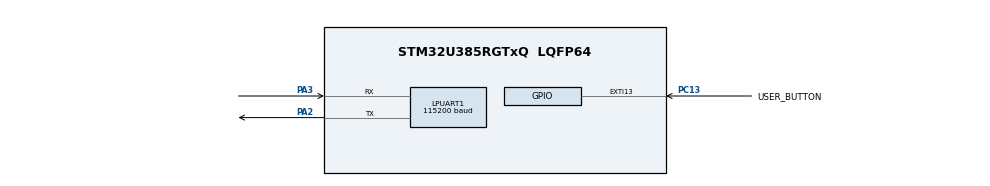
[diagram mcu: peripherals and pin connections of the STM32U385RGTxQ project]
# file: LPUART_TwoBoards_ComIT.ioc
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CORTEX_M33_NS.userName=CORTEX_M33
LPUART1.BaudRate=115200
LPUART1.ClockPrescaler=UART_PRESCALER_DIV1
LPUART1.DMADisableonRxErrorParam=UART_ADVFEATURE_DMA_ENABLEONRXERROR
LPUART1.DataInvertParam=UART_ADVFEATURE_DATAINV_DISABLE
LPUART1.FIFOMode=UART_FIFOMODE_DISABLE
LPUART1.MSBFirstParam=UART_ADVFEATURE_MSBFIRST_DISABLE
LPUART1.Mode=UART_MODE_TX_RX
LPUART1.OneBitSampling=UART_ONE_BIT_SAMPLE_DISABLE
LPUART1.OverrunDisableParam=UART_ADVFEATURE_OVERRUN_ENABLE
LPUART1.Parity=UART_PARITY_NONE
LPUART1.RXFIFOThreshold=UART_RXFIFO_THRESHOLD_1_8
LPUART1.RxPinLevelInvertParam=UART_ADVFEATURE_RXINV_DISABLE
LPUART1.StopBits=UART_STOPBITS_1
LPUART1.SwapParam=UART_ADVFEATURE_SWAP_DISABLE
LPUART1.TXFIFOThreshold=UART_TXFIFO_THRESHOLD_1_8
LPUART1.TxPinLevelInvertParam=UART_ADVFEATURE_TXINV_DISABLE
LPUART1.WordLength=UART_WORDLENGTH_8B
Mcu.Family=STM32U3
Mcu.Name=STM32U385RGTxQ
Mcu.Package=LQFP64
NVIC.EXTI13_IRQn=true\:0\:0\:false\:false\:true\:true\:true\:true
NVIC.LPUART1_IRQn=true\:1\:0\:true\:false\:true\:true\:true\:true
NVIC.PriorityGroup=NVIC_PRIORITYGROUP_4
PA2.GPIO_PuPd=GPIO_PULLUP
PA2.GPIO_Speed=GPIO_SPEED_FREQ_HIGH
PA2.Mode=Asynchronous
PA2.Signal=LPUART1_TX
PA3.GPIO_PuPd=GPIO_PULLUP
PA3.GPIO_Speed=GPIO_SPEED_FREQ_HIGH
PA3.Mode=Asynchronous
PA3.Signal=LPUART1_RX
PC13.GPIO_Label=USER_BUTTON
PC13.GPIO_ModeDefaultEXTI=GPIO_MODE_IT_RISING
PC13.GPIO_PuPd=GPIO_PULLDOWN
PC13.Signal=GPXTI13
ProjectManager.HeapSize=0x200
ProjectManager.StackSize=0x400
ProjectManager.TargetToolchain=EWARM V9.20
RCC.ADCFreq_Value=96000000
RCC.AHBFreq_Value=96000000
RCC.APB1Freq_Value=96000000
RCC.APB1TimFreq_Value=96000000
RCC.APB2Freq_Value=96000000
RCC.APB2TimFreq_Value=96000000
RCC.APB3Freq_Value=96000000
RCC.CortexFreq_Value=12000000
RCC.HCLKFreq_Value=96000000
RCC.HSE_VALUE=16000000
RCC.HSI48_VALUE=48000000
RCC.HSI_VALUE=16000000
RCC.LSE_VALUE=32768
RCC.LSIDIV_VALUE=32000
RCC.MSISDIV=RCC_MSI_DIV1
RCC.MSI_VALUE=96000000
RCC.PWR_Regulator_Voltage_Scale=PWR_REGULATOR_VOLTAGE_SCALE1
RCC.SYSCLKFreq_VALUE=96000000
RCC.USBFreq_Value=96000000
VP_ICACHE_VS_ICACHE.Mode=DirectMappedCache
VP_PWR_VS_DBSignals.Mode=DisableDeadBatterySignals
VP_PWR_VS_LPOM.Mode=PowerOptimisation
VP_PWR_VS_SECSignals.Mode=Security/Privilege
board=custom

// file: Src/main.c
/* USER CODE BEGIN Header */
/**
  ******************************************************************************
  * @file    UART/LPUART_TwoBoards_ComIT/Src/main.c
  * @author  MCD Application Team
  * @brief   This sample code shows how to use LPUART HAL API to transmit
  *          and receive a data buffer with a communication process based on
  *          IT transfer.
  *          The communication is done using 2 Boards.
  ******************************************************************************
  * @attention
  *
  * Copyright (c) 2024 STMicroelectronics.
  * All rights reserved.
  *
  * This software is licensed under terms that can be found in the LICENSE file
  * in the root directory of this software component.
  * If no LICENSE file comes with this software, it is provided AS-IS.
  *
  ******************************************************************************
  */
/* USER CODE END Header */
#include "main.h"

/* USER CODE BEGIN Includes */
#include "stm32u3xx_nucleo.h"
/* USER CODE END Includes */

/* USER CODE BEGIN PD */
//#define TRANSMITTER_BOARD
/* USER CODE END PD */

UART_HandleTypeDef hlpuart1;

/* USER CODE BEGIN PV */
/* UART IT status */
__IO ITStatus UartReady = RESET;
__IO ITStatus UartError = RESET;

/* Buffer used for transmission */
uint8_t aTxBuffer[] = " ****LPUART_TwoBoards_ComIT****  ****LPUART_TwoBoards_ComIT****  ****LPUART_TwoBoards_ComIT**** ";

/* Buffer used for reception */
uint8_t aRxBuffer[RXBUFFERSIZE];
/* USER CODE END PV */

void SystemClock_Config(void);
static void MX_GPIO_Init(void);
static void MX_LPUART1_UART_Init(void);
static void MX_ICACHE_Init(void);
/* USER CODE BEGIN PFP */
static uint16_t Buffercmp(uint8_t* pBuffer1, uint8_t* pBuffer2, uint16_t BufferLength);
/* USER CODE END PFP */

int main(void)
{

  /* USER CODE BEGIN 1 */

  /* STM32U3xx HAL library initialization:
       - Configure the Flash prefetch
       - Configure the Systick to generate an interrupt each 1 msec
       - Set NVIC Group Priority to 3
       - Low Level Initialization
     */
  /* USER CODE END 1 */

  /* MCU Configuration--------------------------------------------------------*/

  /* Reset of all peripherals, Initializes the Flash interface and the Systick. */
  HAL_Init();

  /* Configure the system clock */
  SystemClock_Config();

  /* USER CODE BEGIN SysInit */
  /* Configure LD2 */
  BSP_LED_Init(LD2);
  /* USER CODE END SysInit */

  /* Initialize all configured peripherals */
  MX_GPIO_Init();
  MX_LPUART1_UART_Init();
  MX_ICACHE_Init();
  /* USER CODE BEGIN 2 */

#ifdef TRANSMITTER_BOARD

  /* Configure User push-button */
  BSP_PB_Init(BUTTON_USER, BUTTON_MODE_GPIO);

  /* Toggle LD2 waiting for user to press button */
  BSP_LED_On(LD2);

  /* Wait for User push-button press before starting the Communication */
  while (BSP_PB_GetState(BUTTON_USER) != GPIO_PIN_SET)
  {
  }

  /* Wait for User push-button release before starting the Communication */
  while (BSP_PB_GetState(BUTTON_USER) != GPIO_PIN_RESET)
  {
  }

  /* Turn LD2 off */
  BSP_LED_Off(LD2);

  /* Flush the data registers from unexpected data */
  __HAL_UART_FLUSH_DRREGISTER(&hlpuart1);

  /* The board sends the message and expects to receive it back */

  /*##-1- Start the transmission process #####################################*/
  /* While the LPUART in reception process, user can transmit data through
     "aTxBuffer" buffer */
  if(HAL_UART_Transmit_IT(&hlpuart1, (uint8_t*)aTxBuffer, TXBUFFERSIZE)!= HAL_OK)
  {
    Error_Handler();
  }

  /*##-2- Wait for the end of the transfer ###################################*/
  while ((UartReady != SET)&&(UartError != SET))
  {
  }

  /* Check there was no error */
  if(UartError == SET)
  {
    Error_Handler();
  }

  /* Reset transmission flag */
  UartReady = RESET;

  /*##-3- Put LPUART peripheral in reception process #########################*/
  if(HAL_UART_Receive_IT(&hlpuart1, (uint8_t *)aRxBuffer, RXBUFFERSIZE) != HAL_OK)
  {
    Error_Handler();
  }

#else

  /* The board receives the message and sends it back */

  /*##-1- Put LPUART peripheral in reception process #########################*/
  if(HAL_UART_Receive_IT(&hlpuart1, (uint8_t *)aRxBuffer, RXBUFFERSIZE) != HAL_OK)
  {
    Error_Handler();
  }

  /*##-2- Wait for the end of the transfer ###################################*/
  while ((UartReady != SET)&&(UartError != SET))
  {
  }

  /* Check there was no error */
  if(UartError == SET)
  {
    Error_Handler();
  }

  /* Reset transmission flag */
  UartReady = RESET;

  /* Wait some ms for synchronization */
  HAL_Delay(100);

  /*##-3- Start the transmission process #####################################*/
  /* While the LPUART in reception process, user can transmit data through
     "aTxBuffer" buffer */
  if(HAL_UART_Transmit_IT(&hlpuart1, (uint8_t*)aTxBuffer, TXBUFFERSIZE)!= HAL_OK)
  {
    Error_Handler();
  }

#endif /* TRANSMITTER_BOARD */

  /*##-4- Wait for the end of the transfer ###################################*/
  while ((UartReady != SET)&&(UartError != SET))
  {
  }

  /* Check there was no error */
  if(UartError == SET)
  {
    Error_Handler();
  }

  /* Reset transmission flag */
  UartReady = RESET;

  /*##-5- Compare the sent and received buffers ##############################*/
  if(Buffercmp((uint8_t*)aTxBuffer,(uint8_t*)aRxBuffer,RXBUFFERSIZE))
  {
    Error_Handler();
  }

  /* Turn LD2 on: Transfer process is correct */
  BSP_LED_On(LD2);

  /* USER CODE END 2 */

  /* Infinite loop */
  while (1)
  {

  }
}

void SystemClock_Config(void)
{
  RCC_OscInitTypeDef RCC_OscInitStruct = {0};
  RCC_ClkInitTypeDef RCC_ClkInitStruct = {0};

  /** Enable Epod Booster
  */
  if (HAL_RCCEx_EpodBoosterClkConfig(RCC_EPODBOOSTER_SOURCE_MSIS, RCC_EPODBOOSTER_DIV1) != HAL_OK)
  {
    Error_Handler();
  }

  if (HAL_PWREx_EnableEpodBooster() != HAL_OK)
  {
    Error_Handler();
  }

  /** Configure the main internal regulator output voltage
  */
  if (HAL_PWREx_ControlVoltageScaling(PWR_REGULATOR_VOLTAGE_SCALE1) != HAL_OK)
  {
    Error_Handler();
  }

  /** Set Flash latency before increasing MSIS
  */
  __HAL_FLASH_SET_LATENCY(FLASH_LATENCY_2);

  /** Initializes the CPU, AHB and APB buses clocks
  */
  RCC_OscInitStruct.OscillatorType = RCC_OSCILLATORTYPE_MSIS;
  RCC_OscInitStruct.MSISState = RCC_MSI_ON;
  RCC_OscInitStruct.MSISSource = RCC_MSI_RC0;
  RCC_OscInitStruct.MSISDiv = RCC_MSI_DIV1;
  if (HAL_RCC_OscConfig(&RCC_OscInitStruct) != HAL_OK)
  {
    Error_Handler();
  }

  /** Initializes the CPU, AHB and APB buses clocks
  */
  RCC_ClkInitStruct.ClockType = RCC_CLOCKTYPE_HCLK|RCC_CLOCKTYPE_SYSCLK
                              |RCC_CLOCKTYPE_PCLK1|RCC_CLOCKTYPE_PCLK2
                              |RCC_CLOCKTYPE_PCLK3;
  RCC_ClkInitStruct.SYSCLKSource = RCC_SYSCLKSOURCE_MSIS;
  RCC_ClkInitStruct.AHBCLKDivider = RCC_SYSCLK_DIV1;
  RCC_ClkInitStruct.APB1CLKDivider = RCC_HCLK_DIV1;
  RCC_ClkInitStruct.APB2CLKDivider = RCC_HCLK_DIV1;
  RCC_ClkInitStruct.APB3CLKDivider = RCC_HCLK_DIV1;

  if (HAL_RCC_ClockConfig(&RCC_ClkInitStruct, FLASH_LATENCY_2) != HAL_OK)
  {
    Error_Handler();
  }
}

static void MX_ICACHE_Init(void)
{

  /** Enable instruction cache in 1-way (direct mapped cache)
  */
  if (HAL_ICACHE_ConfigAssociativityMode(ICACHE_1WAY) != HAL_OK)
  {
    Error_Handler();
  }
  if (HAL_ICACHE_Enable() != HAL_OK)
  {
    Error_Handler();
  }

}

static void MX_LPUART1_UART_Init(void)
{

  hlpuart1.Instance = LPUART1;
  hlpuart1.Init.BaudRate = 115200;
  hlpuart1.Init.WordLength = UART_WORDLENGTH_8B;
  hlpuart1.Init.StopBits = UART_STOPBITS_1;
  hlpuart1.Init.Parity = UART_PARITY_NONE;
  hlpuart1.Init.Mode = UART_MODE_TX_RX;
  hlpuart1.Init.HwFlowCtl = UART_HWCONTROL_NONE;
  hlpuart1.Init.OneBitSampling = UART_ONE_BIT_SAMPLE_DISABLE;
  hlpuart1.Init.ClockPrescaler = UART_PRESCALER_DIV1;
  hlpuart1.AdvancedInit.AdvFeatureInit = UART_ADVFEATURE_NO_INIT;
  hlpuart1.FifoMode = UART_FIFOMODE_DISABLE;
  if (HAL_UART_Init(&hlpuart1) != HAL_OK)
  {
    Error_Handler();
  }
  if (HAL_UARTEx_SetTxFifoThreshold(&hlpuart1, UART_TXFIFO_THRESHOLD_1_8) != HAL_OK)
  {
    Error_Handler();
  }
  if (HAL_UARTEx_SetRxFifoThreshold(&hlpuart1, UART_RXFIFO_THRESHOLD_1_8) != HAL_OK)
  {
    Error_Handler();
  }
  if (HAL_UARTEx_DisableFifoMode(&hlpuart1) != HAL_OK)
  {
    Error_Handler();
  }

}

static void MX_GPIO_Init(void)
{
  GPIO_InitTypeDef GPIO_InitStruct = {0};

  /* GPIO Ports Clock Enable */
  __HAL_RCC_GPIOC_CLK_ENABLE();
  __HAL_RCC_GPIOA_CLK_ENABLE();

  /*Configure GPIO pin : USER_BUTTON_Pin */
  GPIO_InitStruct.Pin = USER_BUTTON_Pin;
  GPIO_InitStruct.Mode = GPIO_MODE_IT_RISING;
  GPIO_InitStruct.Pull = GPIO_PULLDOWN;
  HAL_GPIO_Init(USER_BUTTON_GPIO_Port, &GPIO_InitStruct);

  /* EXTI interrupt init*/
  HAL_NVIC_SetPriority(EXTI13_IRQn, 0, 0);
  HAL_NVIC_EnableIRQ(EXTI13_IRQn);

}

/* USER CODE BEGIN 4 */
/**
  * @brief  Tx Transfer completed callback
  * @param  UartHandle: UART handle.
  * @note   This example shows a simple way to report end of IT Tx transfer, and
  *         you can add your own implementation.
  * @retval None
  */
void HAL_UART_TxCpltCallback(UART_HandleTypeDef *UartHandle)
{
  /* Set transmission flag: transfer complete */
  UartReady = SET;
}

/**
  * @brief  Rx Transfer completed callback
  * @param  UartHandle: UART handle
  * @note   This example shows a simple way to report end of IT Rx transfer, and
  *         you can add your own implementation.
  * @retval None
  */
void HAL_UART_RxCpltCallback(UART_HandleTypeDef *UartHandle)
{
  /* Set transmission flag: transfer complete */
  UartReady = SET;
}

/**
  * @brief  UART error callbacks
  * @param  UartHandle: UART handle
  * @note   This example shows a simple way to report transfer error, and you can
  *         add your own implementation.
  * @retval None
  */
void HAL_UART_ErrorCallback(UART_HandleTypeDef *UartHandle)
{
  /* Set error flag */
  UartError = SET;
}

/**
  * @brief  Compares two buffers.
  * @param  pBuffer1, pBuffer2: buffers to be compared.
  * @param  BufferLength: buffer's length
  * @retval 0  : pBuffer1 identical to pBuffer2
  *         >0 : pBuffer1 differs from pBuffer2
  */
static uint16_t Buffercmp(uint8_t* pBuffer1, uint8_t* pBuffer2, uint16_t BufferLength)
{
  while (BufferLength--)
  {
    if ((*pBuffer1) != *pBuffer2)
    {
      return BufferLength;
    }
    pBuffer1++;
    pBuffer2++;
  }

  return 0;
}
/* USER CODE END 4 */

void Error_Handler(void)
{
  /* USER CODE BEGIN Error_Handler_Debug */
  /* User can add his own implementation to report the HAL error return state */
  while(1)
  {
    /* Error if LD2 is slowly blinking (1 sec. period) */
    BSP_LED_Toggle(LD2);
    HAL_Delay(1000);
  }
  /* USER CODE END Error_Handler_Debug */
}
